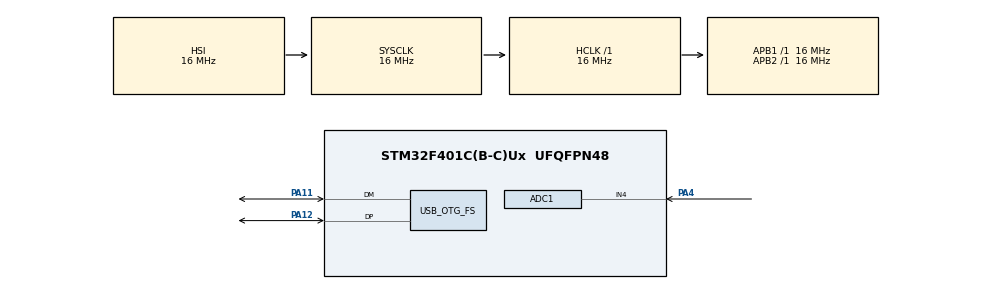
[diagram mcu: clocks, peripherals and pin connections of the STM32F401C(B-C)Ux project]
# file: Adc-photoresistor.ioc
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ADC1.Channel-4\#ChannelRegularConversion=ADC_CHANNEL_4
ADC1.NbrOfConversionFlag=1
ADC1.Rank-4\#ChannelRegularConversion=1
ADC1.SamplingTime-4\#ChannelRegularConversion=ADC_SAMPLETIME_3CYCLES
ADC1.master=1
Mcu.Family=STM32F4
Mcu.Name=STM32F401C(B-C)Ux
Mcu.Package=UFQFPN48
NVIC.OTG_FS_IRQn=true\:0\:0\:false\:false\:true\:false\:true\:true
NVIC.PriorityGroup=NVIC_PRIORITYGROUP_4
PA11.Mode=Device_Only
PA11.Signal=USB_OTG_FS_DM
PA12.Mode=Device_Only
PA12.Signal=USB_OTG_FS_DP
PA4.Signal=ADCx_IN4
PH0\ -\ OSC_IN.Mode=HSE-External-Oscillator
PH0\ -\ OSC_IN.Signal=RCC_OSC_IN
PH1\ -\ OSC_OUT.Mode=HSE-External-Oscillator
PH1\ -\ OSC_OUT.Signal=RCC_OSC_OUT
ProjectManager.HeapSize=0x200
ProjectManager.StackSize=0x400
ProjectManager.TargetToolchain=STM32CubeIDE
RCC.48MHZClocksFreq_Value=48000000
RCC.AHBFreq_Value=16000000
RCC.APB1Freq_Value=16000000
RCC.APB2Freq_Value=16000000
RCC.CortexFreq_Value=16000000
RCC.HSE_VALUE=25000000
RCC.HSI_VALUE=16000000
RCC.LSE_VALUE=32768
RCC.PLLM=15
RCC.PLLN=144
RCC.PLLQ=5
RCC.SYSCLKFreq_VALUE=16000000
RCC.VCOOutputFreq_Value=240000000
SH.ADCx_IN4.0=ADC1_IN4,IN4
USB_DEVICE.CLASS_NAME_FS=CDC
USB_DEVICE.VirtualMode=Cdc
USB_DEVICE.VirtualModeFS=Cdc_FS
USB_OTG_FS.VirtualMode=Device_Only
VP_USB_DEVICE_VS_USB_DEVICE_CDC_FS.Mode=CDC_FS
board=custom

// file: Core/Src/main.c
/* USER CODE BEGIN Header */
/**
  ******************************************************************************
  * @file           : main.c
  * @brief          : Main program body
  ******************************************************************************
  * @attention
  *
  * Copyright (c) 2026 STMicroelectronics.
  * All rights reserved.
  *
  * This software is licensed under terms that can be found in the LICENSE file
  * in the root directory of this software component.
  * If no LICENSE file comes with this software, it is provided AS-IS.
  *
  ******************************************************************************
  */
/* USER CODE END Header */
#include "main.h"
#include "usb_device.h"

/* USER CODE BEGIN Includes */

#include "usbd_cdc_if.h"
#include <stdio.h>

/* USER CODE END Includes */

ADC_HandleTypeDef hadc1;

/* USER CODE BEGIN PV */

uint8_t dataPrint[100];

uint32_t rawValue = 0;
uint32_t voltageMillivolts = 0;

/* USER CODE END PV */

void SystemClock_Config(void);
static void MX_GPIO_Init(void);
static void MX_ADC1_Init(void);
/* USER CODE BEGIN PFP */

uint8_t serial_send(const uint8_t *data, uint16_t len);

/* USER CODE END PFP */

/* USER CODE BEGIN 0 */

uint8_t serial_send(const uint8_t *data, uint16_t len)
{
    if ((data == NULL) || (len == 0))
    {
        return 0;
    }

    if (CDC_Transmit_FS((uint8_t *)data, len) == USBD_OK)
    {
        return 1;
    }

    return 0;
}

/* USER CODE END 0 */

int main(void)
{

  /* MCU Configuration--------------------------------------------------------*/

  /* Reset of all peripherals, Initializes the Flash interface and the Systick. */
  HAL_Init();

  /* Configure the system clock */
  SystemClock_Config();

  /* Initialize all configured peripherals */
  MX_GPIO_Init();
  MX_ADC1_Init();
  MX_USB_DEVICE_Init();
  /* USER CODE BEGIN 2 */

  HAL_Delay(1000);

  /* USER CODE END 2 */

  /* Infinite loop */
  /* USER CODE BEGIN WHILE */
  while (1)
  {
		HAL_ADC_Start(&hadc1);

		if (HAL_ADC_PollForConversion(&hadc1, 100) == HAL_OK) {
			rawValue = HAL_ADC_GetValue(&hadc1);

			voltageMillivolts = (rawValue * 3300UL + 2047UL) / 4095UL;

			int messageLength = snprintf((char*) dataPrint, sizeof(dataPrint),
					"Raw: %lu | Voltage: %lu.%03lu V\r\n",
					(unsigned long) rawValue,
					(unsigned long) (voltageMillivolts / 1000UL),
					(unsigned long) (voltageMillivolts % 1000UL));

			if (messageLength > 0) {
				if (messageLength >= sizeof(dataPrint)) {
					messageLength = sizeof(dataPrint) - 1;
				}

				serial_send(dataPrint, (uint16_t) messageLength);
			}
		}

		HAL_ADC_Stop(&hadc1);

		HAL_Delay(1000);
    /* USER CODE END WHILE */

  }
}

void SystemClock_Config(void)
{
  RCC_OscInitTypeDef RCC_OscInitStruct = {0};
  RCC_ClkInitTypeDef RCC_ClkInitStruct = {0};

  /** Configure the main internal regulator output voltage
  */
  __HAL_RCC_PWR_CLK_ENABLE();
  __HAL_PWR_VOLTAGESCALING_CONFIG(PWR_REGULATOR_VOLTAGE_SCALE2);

  /** Initializes the RCC Oscillators according to the specified parameters
  * in the RCC_OscInitTypeDef structure.
  */
  RCC_OscInitStruct.OscillatorType = RCC_OSCILLATORTYPE_HSI|RCC_OSCILLATORTYPE_HSE;
  RCC_OscInitStruct.HSEState = RCC_HSE_ON;
  RCC_OscInitStruct.HSIState = RCC_HSI_ON;
  RCC_OscInitStruct.HSICalibrationValue = RCC_HSICALIBRATION_DEFAULT;
  RCC_OscInitStruct.PLL.PLLState = RCC_PLL_ON;
  RCC_OscInitStruct.PLL.PLLSource = RCC_PLLSOURCE_HSE;
  RCC_OscInitStruct.PLL.PLLM = 15;
  RCC_OscInitStruct.PLL.PLLN = 144;
  RCC_OscInitStruct.PLL.PLLP = RCC_PLLP_DIV2;
  RCC_OscInitStruct.PLL.PLLQ = 5;
  if (HAL_RCC_OscConfig(&RCC_OscInitStruct) != HAL_OK)
  {
    Error_Handler();
  }

  /** Initializes the CPU, AHB and APB buses clocks
  */
  RCC_ClkInitStruct.ClockType = RCC_CLOCKTYPE_HCLK|RCC_CLOCKTYPE_SYSCLK
                              |RCC_CLOCKTYPE_PCLK1|RCC_CLOCKTYPE_PCLK2;
  RCC_ClkInitStruct.SYSCLKSource = RCC_SYSCLKSOURCE_HSI;
  RCC_ClkInitStruct.AHBCLKDivider = RCC_SYSCLK_DIV1;
  RCC_ClkInitStruct.APB1CLKDivider = RCC_HCLK_DIV1;
  RCC_ClkInitStruct.APB2CLKDivider = RCC_HCLK_DIV1;

  if (HAL_RCC_ClockConfig(&RCC_ClkInitStruct, FLASH_LATENCY_0) != HAL_OK)
  {
    Error_Handler();
  }
}

static void MX_ADC1_Init(void)
{

  ADC_ChannelConfTypeDef sConfig = {0};

  /** Configure the global features of the ADC (Clock, Resolution, Data Alignment and number of conversion)
  */
  hadc1.Instance = ADC1;
  hadc1.Init.ClockPrescaler = ADC_CLOCK_SYNC_PCLK_DIV2;
  hadc1.Init.Resolution = ADC_RESOLUTION_12B;
  hadc1.Init.ScanConvMode = DISABLE;
  hadc1.Init.ContinuousConvMode = DISABLE;
  hadc1.Init.DiscontinuousConvMode = DISABLE;
  hadc1.Init.ExternalTrigConvEdge = ADC_EXTERNALTRIGCONVEDGE_NONE;
  hadc1.Init.ExternalTrigConv = ADC_SOFTWARE_START;
  hadc1.Init.DataAlign = ADC_DATAALIGN_RIGHT;
  hadc1.Init.NbrOfConversion = 1;
  hadc1.Init.DMAContinuousRequests = DISABLE;
  hadc1.Init.EOCSelection = ADC_EOC_SINGLE_CONV;
  if (HAL_ADC_Init(&hadc1) != HAL_OK)
  {
    Error_Handler();
  }

  /** Configure for the selected ADC regular channel its corresponding rank in the sequencer and its sample time.
  */
  sConfig.Channel = ADC_CHANNEL_4;
  sConfig.Rank = 1;
  sConfig.SamplingTime = ADC_SAMPLETIME_3CYCLES;
  if (HAL_ADC_ConfigChannel(&hadc1, &sConfig) != HAL_OK)
  {
    Error_Handler();
  }

}

static void MX_GPIO_Init(void)
{

  /* GPIO Ports Clock Enable */
  __HAL_RCC_GPIOH_CLK_ENABLE();
  __HAL_RCC_GPIOA_CLK_ENABLE();

}

void Error_Handler(void)
{
  __disable_irq();
  while (1)
  {
  }
}
